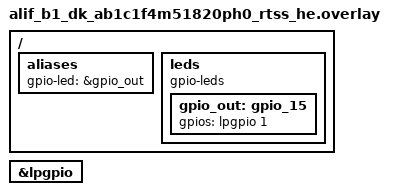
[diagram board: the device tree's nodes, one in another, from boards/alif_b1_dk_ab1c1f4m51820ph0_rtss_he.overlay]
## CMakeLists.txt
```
# Copyright (C) 2024 Alif Semiconductor - All Rights Reserved.
# Use, distribution and modification of this code is permitted under the
# terms stated in the Alif Semiconductor Software License Agreement
#
# You should have received a copy of the Alif Semiconductor Software
# License Agreement with this file. If not, please write to:
# contact@alifsemi.com, or visit: https://alifsemi.com/license

cmake_minimum_required(VERSION 3.20.0)

# Include BLE Power Management snippet by default
if(NOT pm-ble IN_LIST SNIPPET)
  set(SNIPPET pm-ble ${SNIPPET} CACHE STRING "" FORCE)
endif()

find_package(Zephyr REQUIRED HINTS $ENV{ZEPHYR_BASE})
project(le_periph)

target_sources(app PRIVATE
    src/main.c
)
```

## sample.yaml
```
sample:
  name: LE Periph
tests:
  sample.bt_custom.le_periph:
    build_only: true
    filter: dt_alias_exists("led0")
    tags:
      - bluetooth
      - bt_custom
```

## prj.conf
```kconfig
CONFIG_USE_SEGGER_RTT=y
CONFIG_RTT_CONSOLE=y
CONFIG_BT=y
CONFIG_BT_CUSTOM=y

CONFIG_LOG=y
CONFIG_ASSERT=y

# Enable UART async API
CONFIG_DMA=y
CONFIG_UART_ASYNC_API=y
```

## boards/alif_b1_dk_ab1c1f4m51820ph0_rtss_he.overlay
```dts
/* Copyright (C) Alif Semiconductor - All Rights Reserved.
 * Use, distribution and modification of this code is permitted under the
 * terms stated in the Alif Semiconductor Software License Agreement
 *
 * You should have received a copy of the Alif Semiconductor Software
 * License Agreement with this file. If not, please write to:
 * contact@alifsemi.com, or visit: https://alifsemi.com/license
 */

/ {
	aliases {
		gpio-led = &gpio_out;
	};

	leds {
		compatible = "gpio-leds";
		gpio_out: gpio_15 {
			gpios = <&lpgpio 1 0>;
		};
	};
};

&lpgpio {
	status = "okay";
};
```

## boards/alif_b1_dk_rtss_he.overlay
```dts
#define HCI_UART_DMA_RX_CH  0
#define HCI_UART_DMA_RX_REQ 26
#define HCI_UART_DMA_TX_CH  1
#define HCI_UART_DMA_TX_REQ 27

&dma2 {
	status = "okay";
	dma-channels = <8>;
	interrupts = <0 3>, <1 3>, <2 3>, <3 3>, <4 3>, <5 3>,
		     <6 3>, <7 3>, <32 3>;
	interrupt-names = "channel0", "channel1",
			  "channel2", "channel3",
			  "channel4", "channel5",
			  "channel6", "channel7",
			  "abort";
};

/* Group0 is used so no EVTRTR2 configuration needed */
&uart_hci {
	dmas = <&dma2 HCI_UART_DMA_RX_CH HCI_UART_DMA_RX_REQ>,
	       <&dma2 HCI_UART_DMA_TX_CH HCI_UART_DMA_TX_REQ>;
	dma-names = "rx", "tx";
};
```

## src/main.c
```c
/* Copyright (C) 2025 Alif Semiconductor - All Rights Reserved.
 * Use, distribution and modification of this code is permitted under the
 * terms stated in the Alif Semiconductor Software License Agreement
 *
 * You should have received a copy of the Alif Semiconductor Software
 * License Agreement with this file. If not, please write to:
 * contact@alifsemi.com, or visit: https://alifsemi.com/license
 */

#include <zephyr/kernel.h>
#include <zephyr/logging/log.h>
#include "alif_ble.h"
#include "gapm.h"
#include "gap_le.h"
#include "gapc_le.h"
#include "gapc_sec.h"
#include "gapm_le.h"
#include "gapm_le_adv.h"
#include "co_buf.h"
#include "address_verification.h"
#include <alif/bluetooth/bt_adv_data.h>
#include <alif/bluetooth/bt_scan_rsp.h>
#include "gapm_api.h"
#include "ble_gpio.h"

LOG_MODULE_REGISTER(main, LOG_LEVEL_DBG);

/* Define advertising address type */
#define SAMPLE_ADDR_TYPE	ALIF_STATIC_RAND_ADDR

#ifdef CONFIG_PM
#define LED0_NODE DT_ALIAS(gpio_led)
#else
#define LED0_NODE DT_ALIAS(led0)
#endif

static const struct gpio_dt_spec led2 = GPIO_DT_SPEC_GET(LED0_NODE, gpios);

/* Store and share advertising address type */
static uint8_t adv_type;
static uint8_t conn_status = BT_CONN_STATE_DISCONNECTED;

/**
 * Bluetooth stack configuration
 */
static gapm_config_t gapm_cfg = {
	.role = GAP_ROLE_LE_PERIPHERAL,
	.pairing_mode = GAPM_PAIRING_DISABLE,
	.privacy_cfg = 0,
	.renew_dur = 1500,
	.private_identity.addr = {0, 0, 0, 0, 0, 0},
	.irk.key = {0, 0, 0, 0, 0, 0, 0, 0, 0, 0, 0, 0, 0, 0, 0, 0},
	.gap_start_hdl = 0,
	.gatt_start_hdl = 0,
	.att_cfg = 0,
	.sugg_max_tx_octets = GAP_LE_MIN_OCTETS,
	.sugg_max_tx_time = GAP_LE_MIN_TIME,
	.tx_pref_phy = GAP_PHY_ANY,
	.rx_pref_phy = GAP_PHY_ANY,
	.tx_path_comp = 0,
	.rx_path_comp = 0,
	.class_of_device = 0,  /* BT Classic only */
	.dflt_link_policy = 0, /* BT Classic only */
};

static const char *device_name = "ALIF_ZEPHYR";
/* Store advertising activity index for re-starting after disconnection */
static uint8_t adv_actv_idx;

void LedWorkerHandler(struct k_work *work);
static K_WORK_DELAYABLE_DEFINE(ledWork, LedWorkerHandler);

void LedWorkerHandler(struct k_work *work)
{
	int res_schedule_time = 0;

	if (conn_status == BT_CONN_STATE_CONNECTED) {
		ble_gpio_led_set(&led2, false);
	} else {
		ble_gpio_led_toggle(&led2);
		res_schedule_time = 500;
	}

	if (res_schedule_time) {
		k_work_reschedule(&ledWork, K_MSEC(res_schedule_time));
	}
}

static void UpdateMuteLedstate(void)
{
	k_work_reschedule(&ledWork, K_MSEC(1));
}

static int set_advertising_data(uint8_t actv_idx)
{
	int ret;

	ret = bt_adv_data_set_name_auto(device_name, strlen(device_name));

	if (ret) {
		LOG_ERR("AD device name data fail %d", ret);
		return ATT_ERR_INSUFF_RESOURCE;
	}

	return bt_gapm_advertiment_data_set(actv_idx);
}

static uint16_t create_advertising(void)
{
	gapm_le_adv_create_param_t adv_create_params = {
		.prop = GAPM_ADV_PROP_UNDIR_CONN_MASK,
		.disc_mode = GAPM_ADV_MODE_GEN_DISC,
		.tx_pwr = 0,
		.filter_pol = GAPM_ADV_ALLOW_SCAN_ANY_CON_ANY,
		.prim_cfg = {
			.adv_intv_min = 160, /* 100 ms */
			.adv_intv_max = 800, /* 500 ms */
			.ch_map = ADV_ALL_CHNLS_EN,
			.phy = GAPM_PHY_TYPE_LE_1M,
		},
	};

	return bt_gapm_le_create_advertisement_service(GAPM_STATIC_ADDR, &adv_create_params, NULL,
						      &adv_actv_idx);
}

void app_connection_status_update(enum gapm_connection_event con_event, uint8_t con_idx,
				  uint16_t status)
{
	switch (con_event) {
	case GAPM_API_SEC_CONNECTED_KNOWN_DEVICE:
		conn_status = BT_CONN_STATE_CONNECTED;
		LOG_INF("Connection index %u connected to known device", con_idx);
		break;
	case GAPM_API_DEV_CONNECTED:
		conn_status = BT_CONN_STATE_CONNECTED;
		LOG_INF("Connection index %u connected to new device", con_idx);
		break;
	case GAPM_API_DEV_DISCONNECTED:
		LOG_INF("Connection index %u disconnected for reason %u", con_idx, status);
		conn_status = BT_CONN_STATE_DISCONNECTED;
		break;
	case GAPM_API_PAIRING_FAIL:
		LOG_INF("Connection pairing index %u fail for reason %u", con_idx, status);
		break;
	}

	UpdateMuteLedstate();
}

static gapm_user_cb_t gapm_user_cb = {
	.connection_status_update = app_connection_status_update,
};

int main(void)
{
	uint16_t err;

	err = ble_gpio_led_init();

	if (err) {
		LOG_ERR("Led Init fail %u", err);
		return -1;
	}

	/* Start up bluetooth host stack */
	alif_ble_enable(NULL);

	if (address_verification(SAMPLE_ADDR_TYPE, &adv_type, &gapm_cfg)) {
		LOG_ERR("Address verification failed");
		return -EADV;
	}

	LOG_INF("Init gapm service");
	err = bt_gapm_init(&gapm_cfg, &gapm_user_cb, device_name, strlen(device_name));
	if (err) {
		LOG_ERR("gapm_configure error %u", err);
		return -1;
	}

	err = create_advertising();
	if (err) {
		LOG_ERR("Advertisement create fail %u", err);
		return -1;
	}

	err = set_advertising_data(adv_actv_idx);
	if (err) {
		LOG_ERR("Advertisement data set fail %u", err);
		return -1;
	}

	err = bt_gapm_scan_response_set(adv_actv_idx);
	if (err) {
		LOG_ERR("Scan response set fail %u", err);
		return -1;
	}

	err = bt_gapm_advertisement_start(adv_actv_idx);
	if (err) {
		LOG_ERR("Advertisement start fail %u", err);
		return -1;
	}

	print_device_identity();
	/* Set a Led init state */
	k_work_reschedule(&ledWork, K_MSEC(1));

	uint32_t ctr = 0;

	while (1) {
		LOG_DBG("blink %u", ctr++);
		k_sleep(K_SECONDS(5));
	}
}
```
